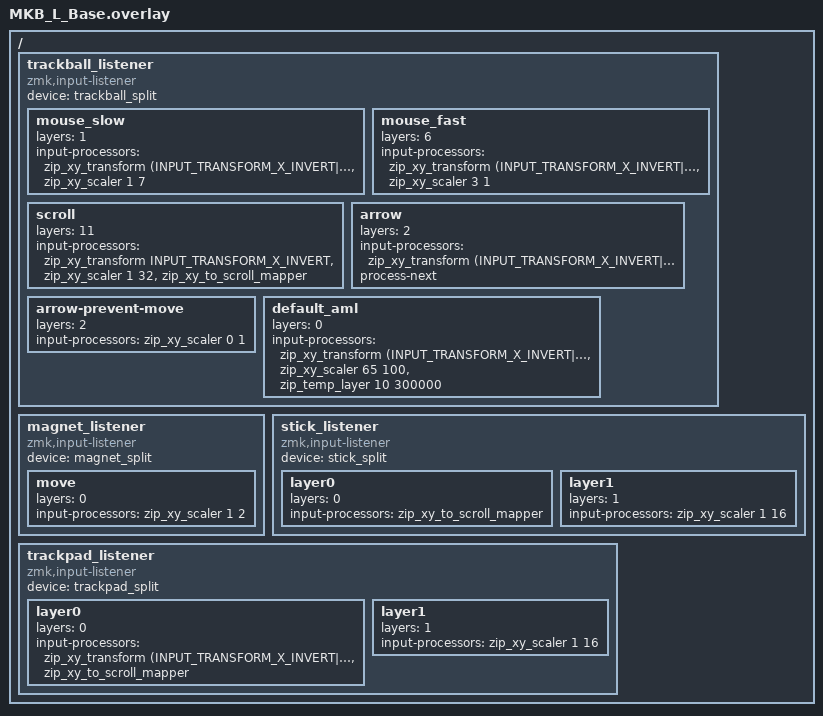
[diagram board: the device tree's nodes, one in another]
/ {
    trackball_listener: trackball_listener {
        compatible = "zmk,input-listener";
        status = "okay";
        device = <&trackball_split>;
        // input-processors = <&zip_xy_transform (INPUT_TRANSFORM_X_INVERT|INPUT_TRANSFORM_Y_INVERT)>, <&zip_xy_scaler 1 1>, <&zip_temp_layer 8 300000>;
        
        mouse_slow {
            layers = <1>; // layer8は今未使用
            input-processors =
            <&zip_xy_transform (INPUT_TRANSFORM_X_INVERT|INPUT_TRANSFORM_Y_INVERT)>,
                <&zip_xy_scaler 1 7>;
        };

        mouse_fast {
            layers = <6>; // layer9は今未使用
            input-processors =
            <&zip_xy_transform (INPUT_TRANSFORM_X_INVERT|INPUT_TRANSFORM_Y_INVERT)>,
                <&zip_xy_scaler 3 1>;
        };

        scroll {
            layers = <11>;
            input-processors = <&zip_xy_transform INPUT_TRANSFORM_X_INVERT>, <&zip_xy_scaler 1 32>, <&zip_xy_to_scroll_mapper>;
        };

        // cursolレイヤーではTB無効化
        arrow {
            layers = <2>;
            input-processors = <&zip_xy_transform (INPUT_TRANSFORM_X_INVERT|INPUT_TRANSFORM_Y_INVERT)>;
            process-next;
        };
        arrow-prevent-move {
            layers = <2>;
            input-processors = <&zip_xy_scaler 0 1>;
        };

        // デフォルトレイヤーは一番最後！
        default_aml {
            layers = <0>;
            input-processors = 
                <&zip_xy_transform (INPUT_TRANSFORM_X_INVERT|INPUT_TRANSFORM_Y_INVERT)>,
                <&zip_xy_scaler 65 100>,
                <&zip_temp_layer 10 300000>; 
        };
    };

    magnet_listener: magnet_listener {
        compatible = "zmk,input-listener";
        status = "okay";
        device = <&magnet_split>;
        move {
            layers = <0>;
            input-processors = 
                                // <&zip_xy_transform (INPUT_TRANSFORM_XY_SWAP)>,
                                <&zip_xy_scaler 1 2>;
        };
    };

    stick_listener: stick_listener {
        compatible = "zmk,input-listener";
        status = "okay";
        device = <&stick_split>;
        
        layer0 {
            layers = <0>;
            input-processors = <&zip_xy_to_scroll_mapper>;
        };
        layer1 {
            layers = <1>;
            input-processors = <&zip_xy_scaler 1 16>;
        };
    };
    
    trackpad_listener: trackpad_listener {
        compatible = "zmk,input-listener";
        status = "okay";
        device = <&trackpad_split>;
        
        layer0 {
            layers = <0>;
            input-processors = <&zip_xy_transform (INPUT_TRANSFORM_X_INVERT|INPUT_TRANSFORM_Y_INVERT)>, <&zip_xy_to_scroll_mapper>;
        };
        layer1 {
            layers = <1>;
            input-processors = <&zip_xy_scaler 1 16>;
        };
    };
};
